# ATmega324PB register map
Vendor: Atmel; File version: 1.0
CPU: other r0p0, little endian, no MPU, no FPU, 4 interrupt priority bits
Registers are 8-bit, read-write, reset 0x0 unless marked. A register's access mark holds for its fields unless they carry their own. Offsets are from the block's base; [hi:lo] are bit positions; {n}, {i} and the like mark numbered series.

## AC — Analog Comparator
Base 0x0080004F
0x00 ACSRB — Analog Comparator Control And Status Register B (read-only for debugger)
  [0] ACOE — Analog Comparator Output enable
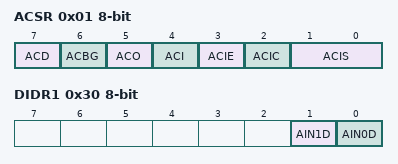
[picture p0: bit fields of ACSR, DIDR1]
0x01 ACSR — Analog Comparator Control And Status Register (read-only for debugger)
  [7] ACD — Analog Comparator Disable
  [6] ACBG — Analog Comparator Bandgap Select
  [5] ACO — Analog Compare Output
  [4] ACI — Analog Comparator Interrupt Flag
  [3] ACIE — Analog Comparator Interrupt Enable
  [2] ACIC — Analog Comparator Input Capture Enable
  [1:0] ACIS — Analog Comparator Interrupt Mode Select bits
    0=INTERRUPT_ON_TOGGLE; 2=INTERRUPT_ON_FALLING_EDGE; 3=INTERRUPT_ON_RISING_EDGE
0x30 DIDR1 — Digital Input Disable Register 1
  [1] AIN1D — AIN1 Digital Input Disable
  [0] AIN0D — AIN0 Digital Input Disable

## ADC — Analog-to-Digital Converter
Base 0x00800078
0x00 ADC 16-bit (reset mask 0xFF) — ADC Data Register Bytes
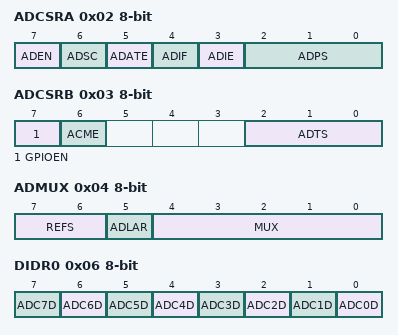
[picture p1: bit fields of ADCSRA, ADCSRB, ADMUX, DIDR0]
0x02 ADCSRA — ADC Control and Status register A (read-only for debugger)
  [7] ADEN — ADC Enable
  [6] ADSC — ADC Start Conversion
  [5] ADATE — ADC Auto Trigger Enable
  [4] ADIF — ADC Interrupt Flag
  [3] ADIE — ADC Interrupt Enable
  [2:0] ADPS — ADC Prescaler Select Bits
    1=2; 2=4; 3=8; 4=16; 5=32; 6=64; 7=128
0x03 ADCSRB — ADC Control and Status register B
  [7] GPIOEN — Enable GPIO function of PE4
  [6] ACME — Analog Comparator Multiplexer Enable
  [2:0] ADTS — ADC Auto Trigger Source bits
    0=FREE_RUNNING_MODE; 1=ANALOG_COMPARATOR; 2=EXTERNAL_INTERRUPT_REQUEST_0; 3=TIMER_COUNTER0_COMPARE_MATCH_A; 4=TIMER_COUNTER0_OVERFLOW; 5=TIMER_COUNTER1_COMPARE_MATCH_B; 6=TIMER_COUNTER1_OVERFLOW; 7=TIMER_COUNTER1_CAPTURE_EVENT
0x04 ADMUX — ADC multiplexer Selection Register
  [7:6] REFS — Reference Selection Bits
    0=AREF_INTERNAL_VREF_TURNED_OFF; 1=AVCC_WITH_EXTERNAL_CAPACITOR_AT_AREF_PIN; 2=INTERNAL_1_1V_VOLTAGE_REFERENCE_WITH_EXTERNAL_CAPACITOR_AT_AREF_PIN; 3=INTERNAL_2_56V_VOLTAGE_REFERENCE_WITH_EXTERNAL_CAPACITOR_AT_AREF_PIN
  [5] ADLAR — Left Adjust Result
  [4:0] MUX — Analog Channel and Gain Selection Bits
    {v}=ADC{v} (ADC Single Ended Input pin {v}) (v=0..7); 8=ADC0_ADC0_10X (ADC Differential Inputs Positive pin 0 Negative pin 0 10x Gain); 9=ADC1_ADC0_10X (ADC Differential Inputs Positive pin 1 Negative pin 0 10x Gain); 10=ADC0_ADC0_200x (ADC Differential Inputs Positive pin 0 Negative pin 0 200x Gain); 11=ADC1_ADC0_200X (ADC Differential Inputs Positive pin 1 Negative pin 0 200x Gain); 12=ADC2_ADC2_10X (ADC Differential Inputs Positive pin 2 Negative pin 2 10x Gain); 13=ADC3_ADC2_10X (ADC Differential Inputs Positive pin 3 Negative pin 2 10x Gain); 14=ADC2_ADC2_200X (ADC Differential Inputs Positive pin 2 Negative pin 2 200x Gain); 15=ADC3_ADC2_200X (ADC Differential Inputs Positive pin 3 Negative pin 2 200x Gain); {v}=ADC{v-16}_ADC1_1X (ADC Differential Inputs Positive pin {v-16} Negative pin 1 1x Gain) (v=16..23); {v}=ADC{v-24}_ADC2_1X (ADC Differential Inputs Positive pin {v-24} Negative pin 2 1x Gain) (v=24..29); 30=ADC_VBG (Internal Reference (VBG)); 31=ADC_GND (0V (GND))
0x06 DIDR0 — Digital Input Disable Register
  [n] ADC{n}D (n=0..7)

## CFD — Clock Failure Detection
Base 0x00800062
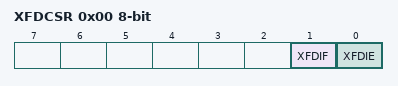
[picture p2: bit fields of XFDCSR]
0x00 XFDCSR — XOSC Failure Detection Control and Status Register
  [1] XFDIF — Failure Detection Interrupt Flag
  [0] XFDIE — Failure Detection Interrupt Enable

## CPU — CPU Registers
Base 0x0080003E
0x00 GPIOR0 — General Purpose IO Register 0
0x0C GPIOR1 — General Purpose IO Register 1
0x0D GPIOR2 — General Purpose IO Register 2
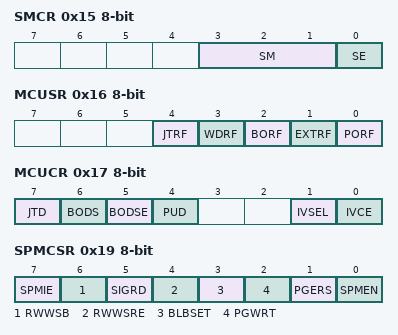
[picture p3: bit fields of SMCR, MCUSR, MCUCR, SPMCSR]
0x15 SMCR — Sleep Mode Control Register
  [3:1] SM — Sleep Mode Select bits
    0=IDLE; 1=ADC (ADC Noise Reduction (If Available)); 2=PDOWN (Power Down); 3=PSAVE (Power Save); 6=STDBY (Standby); 7=ESTDBY (Extended Standby)
  [0] SE — Sleep Enable
0x16 MCUSR — MCU Status Register
  [4] JTRF — JTAG Reset Flag
  [3] WDRF — Watchdog Reset Flag
  [2] BORF — Brown-out Reset Flag
  [1] EXTRF — External Reset Flag
  [0] PORF — Power-on reset flag
0x17 MCUCR — MCU Control Register
  [7] JTD — JTAG Interface Disable
  [6] BODS — BOD Power Down in Sleep
  [5] BODSE — BOD Power Down in Sleep Enable
  [4] PUD — Pull-up disable
  [1] IVSEL — Interrupt Vector Select
  [0] IVCE — Interrupt Vector Change Enable
0x19 SPMCSR — Store Program Memory Control Register
  [7] SPMIE — SPM Interrupt Enable
  [6] RWWSB — Read While Write Section Busy
  [5] SIGRD — Signature Row Read
  [4] RWWSRE — Read While Write section read enable
  [3] BLBSET — Boot Lock Bit Set
  [2] PGWRT — Page Write
  [1] PGERS — Page Erase
  [0] SPMEN — Store Program Memory Enable
0x1F SP 16-bit (reset mask 0xFF) — Stack Pointer
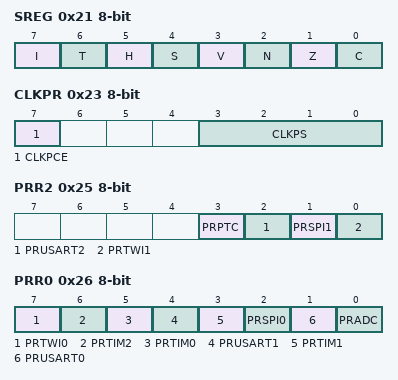
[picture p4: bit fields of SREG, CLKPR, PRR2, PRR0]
0x21 SREG — Status Register
  [7] I — Global Interrupt Enable
  [6] T — Bit Copy Storage
  [5] H — Half Carry Flag
  [4] S — Sign Bit
  [3] V — Two's Complement Overflow Flag
  [2] N — Negative Flag
  [1] Z — Zero Flag
  [0] C — Carry Flag
0x23 CLKPR
  [7] CLKPCE
  [3:0] CLKPS
    0=1; 1=2; 2=4; 3=8; 4=16; 5=32; 6=64; 7=128; 8=256
0x25 PRR2 — Power Reduction Register2
  [3] PRPTC — Power Reduction Peripheral Touch Controller
  [2] PRUSART2 — Power Reduction USART2
  [1] PRSPI1 — Power Reduction Serial Peripheral Interface 1
  [0] PRTWI1 — Power Reduction TWI1
0x26 PRR0 — Power Reduction Register0
  [7] PRTWI0 — Power Reduction TWI0
  [6] PRTIM2 — Power Reduction Timer/Counter2
  [5] PRTIM0 — Power Reduction Timer/Counter0
  [4] PRUSART1 — Power Reduction USART1
  [3] PRTIM1 — Power Reduction Timer/Counter1
  [2] PRSPI0 — Power Reduction Serial Peripheral Interface 0
  [1] PRUSART0 — Power Reduction USART0
  [0] PRADC — Power Reduction ADC
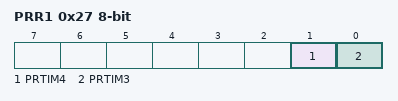
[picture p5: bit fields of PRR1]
0x27 PRR1 — Power Reduction Register1
  [1] PRTIM4 — Power Reduction Timer/Counter4
  [0] PRTIM3 — Power Reduction Timer/Counter3
0x28 OSCCAL — Oscillator Calibration Value
  [7:0] OSCCAL — Oscillator Calibration
